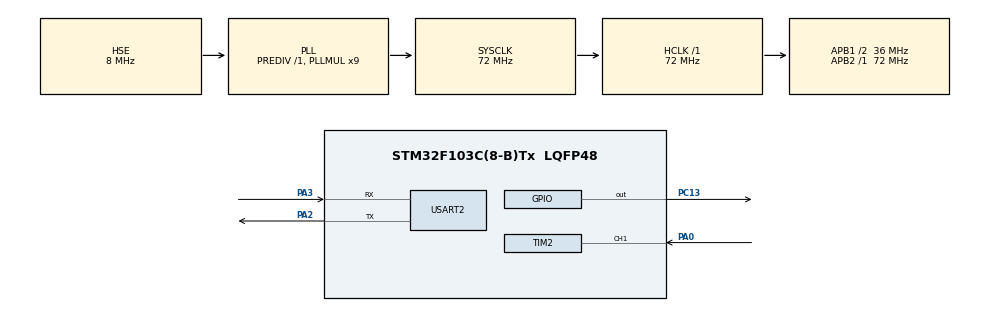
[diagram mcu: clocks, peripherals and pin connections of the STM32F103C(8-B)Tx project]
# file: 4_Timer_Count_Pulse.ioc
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Mcu.Family=STM32F1
RCC.PLLSourceVirtual=RCC_PLLSOURCE_HSE
PD1-OSC_OUT.Mode=HSE-External-Oscillator
PC13-TAMPER-RTC.Signal=GPIO_Output
PD0-OSC_IN.Signal=RCC_OSC_IN
RCC.APB1CLKDivider=RCC_HCLK_DIV2
RCC.SYSCLKSource=RCC_SYSCLKSOURCE_PLLCLK
ProjectManager.StackSize=0x400
PA0-WKUP.Signal=S_TIM2_CH1_ETR
PD1-OSC_OUT.Signal=RCC_OSC_OUT
PA13.Signal=SYS_JTMS-SWDIO
PA3.Mode=Asynchronous
ProjectManager.TargetToolchain=STM32CubeIDE
VP_TIM2_VS_ControllerModeClock.Mode=Clock Mode
RCC.HCLKFreq_Value=72000000
RCC.APB2TimFreq_Value=72000000
RCC.USBFreq_Value=72000000
RCC.AHBFreq_Value=72000000
PD0-OSC_IN.Mode=HSE-External-Oscillator
board=custom
RCC.PLLMUL=RCC_PLL_MUL9
RCC.APB2Freq_Value=72000000
PA14.Mode=Serial_Wire
TIM2.Period=1000
PA13.Mode=Serial_Wire
Mcu.Name=STM32F103C(8-B)Tx
PA2.Signal=USART2_TX
RCC.SYSCLKFreq_VALUE=72000000
Mcu.Package=LQFP48
USART2.VirtualMode=VM_ASYNC
SH.S_TIM2_CH1_ETR.0=TIM2_CH1,TriggerSource_TI1FP1
PA14.Signal=SYS_JTCK-SWCLK
ProjectManager.HeapSize=0x200
NVIC.PriorityGroup=NVIC_PRIORITYGROUP_4
RCC.APB1TimFreq_Value=72000000
PA2.Mode=Asynchronous
PA0-WKUP.GPIO_PuPd=GPIO_PULLDOWN
RCC.APB1Freq_Value=36000000
PA3.Signal=USART2_RX

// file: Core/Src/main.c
/* USER CODE BEGIN Header */
/**
  ******************************************************************************
  * @file           : main.c
  * @brief          : Main program body
  ******************************************************************************
  * @attention
  *
  * <h2><center>&copy; Copyright (c) 2021 STMicroelectronics.
  * All rights reserved.</center></h2>
  *
  * This software component is licensed by ST under BSD 3-Clause license,
  * the "License"; You may not use this file except in compliance with the
  * License. You may obtain a copy of the License at:
  *                        opensource.org/licenses/BSD-3-Clause
  *
  ******************************************************************************
  */
/* Input PA0 Pull down mode to prevent noise, which can cause problems
 * Using timer 2 to detect rising edge of pulse by pressing button*/

/* USER CODE END Header */
#include "main.h"

/* USER CODE BEGIN Includes */
#include "stdio.h"
/* USER CODE END Includes */

TIM_HandleTypeDef htim2;

UART_HandleTypeDef huart2;

void SystemClock_Config(void);
static void MX_GPIO_Init(void);
static void MX_TIM2_Init(void);
static void MX_USART2_UART_Init(void);

/* USER CODE BEGIN 0 */
uint8_t count ;
uint8_t temp ;
uint8_t Buff[4];
//This function for console view
int _write(int file, char *ptr, int len)
{
  /* Implement your write code here, this is used by puts and printf for example */
  int i=0;
  for(i=0 ; i<len ; i++)
    ITM_SendChar((*ptr++));
  return len;
}
/* USER CODE END 0 */

int main(void)
{

  /* MCU Configuration--------------------------------------------------------*/

  /* Reset of all peripherals, Initializes the Flash interface and the Systick. */
  HAL_Init();

  /* Configure the system clock */
  SystemClock_Config();

  /* Initialize all configured peripherals */
  MX_GPIO_Init();
  MX_TIM2_Init();
  MX_USART2_UART_Init();
  /* USER CODE BEGIN 2 */
	HAL_TIM_Base_Start(&htim2);
  /* USER CODE END 2 */

  /* Infinite loop */
  while (1)
  {

    /* USER CODE BEGIN 3 */
		count = (uint8_t)__HAL_TIM_GET_COUNTER(&htim2);
//		if(temp != count)
//		{
//			sprintf(Buff,"%d",count);
//			//HAL_UART_Transmit(&huart2, &temp, 1, HAL_MAX_DELAY);
//			HAL_GPIO_TogglePin(GPIOC, GPIO_PIN_13);
//			temp = count;
//			HAL_UART_Transmit(&huart2, Buff, 1, 500);
//		}

  }
  /* USER CODE END 3 */
}

void SystemClock_Config(void)
{
  RCC_OscInitTypeDef RCC_OscInitStruct = {0};
  RCC_ClkInitTypeDef RCC_ClkInitStruct = {0};

  /** Initializes the RCC Oscillators according to the specified parameters
  * in the RCC_OscInitTypeDef structure.
  */
  RCC_OscInitStruct.OscillatorType = RCC_OSCILLATORTYPE_HSE;
  RCC_OscInitStruct.HSEState = RCC_HSE_ON;
  RCC_OscInitStruct.HSEPredivValue = RCC_HSE_PREDIV_DIV1;
  RCC_OscInitStruct.HSIState = RCC_HSI_ON;
  RCC_OscInitStruct.PLL.PLLState = RCC_PLL_ON;
  RCC_OscInitStruct.PLL.PLLSource = RCC_PLLSOURCE_HSE;
  RCC_OscInitStruct.PLL.PLLMUL = RCC_PLL_MUL9;
  if (HAL_RCC_OscConfig(&RCC_OscInitStruct) != HAL_OK)
  {
    Error_Handler();
  }
  /** Initializes the CPU, AHB and APB buses clocks
  */
  RCC_ClkInitStruct.ClockType = RCC_CLOCKTYPE_HCLK|RCC_CLOCKTYPE_SYSCLK
                              |RCC_CLOCKTYPE_PCLK1|RCC_CLOCKTYPE_PCLK2;
  RCC_ClkInitStruct.SYSCLKSource = RCC_SYSCLKSOURCE_PLLCLK;
  RCC_ClkInitStruct.AHBCLKDivider = RCC_SYSCLK_DIV1;
  RCC_ClkInitStruct.APB1CLKDivider = RCC_HCLK_DIV2;
  RCC_ClkInitStruct.APB2CLKDivider = RCC_HCLK_DIV1;

  if (HAL_RCC_ClockConfig(&RCC_ClkInitStruct, FLASH_LATENCY_2) != HAL_OK)
  {
    Error_Handler();
  }
}

static void MX_TIM2_Init(void)
{

  TIM_SlaveConfigTypeDef sSlaveConfig = {0};
  TIM_MasterConfigTypeDef sMasterConfig = {0};

  htim2.Instance = TIM2;
  htim2.Init.Prescaler = 0;
  htim2.Init.CounterMode = TIM_COUNTERMODE_UP;
  htim2.Init.Period = 1000;
  htim2.Init.ClockDivision = TIM_CLOCKDIVISION_DIV1;
  htim2.Init.AutoReloadPreload = TIM_AUTORELOAD_PRELOAD_DISABLE;
  if (HAL_TIM_Base_Init(&htim2) != HAL_OK)
  {
    Error_Handler();
  }
  sSlaveConfig.SlaveMode = TIM_SLAVEMODE_EXTERNAL1;
  sSlaveConfig.InputTrigger = TIM_TS_TI1FP1;
  sSlaveConfig.TriggerPolarity = TIM_TRIGGERPOLARITY_RISING;
  sSlaveConfig.TriggerFilter = 0;
  if (HAL_TIM_SlaveConfigSynchro(&htim2, &sSlaveConfig) != HAL_OK)
  {
    Error_Handler();
  }
  sMasterConfig.MasterOutputTrigger = TIM_TRGO_RESET;
  sMasterConfig.MasterSlaveMode = TIM_MASTERSLAVEMODE_DISABLE;
  if (HAL_TIMEx_MasterConfigSynchronization(&htim2, &sMasterConfig) != HAL_OK)
  {
    Error_Handler();
  }

}

static void MX_USART2_UART_Init(void)
{

  huart2.Instance = USART2;
  huart2.Init.BaudRate = 115200;
  huart2.Init.WordLength = UART_WORDLENGTH_8B;
  huart2.Init.StopBits = UART_STOPBITS_1;
  huart2.Init.Parity = UART_PARITY_NONE;
  huart2.Init.Mode = UART_MODE_TX_RX;
  huart2.Init.HwFlowCtl = UART_HWCONTROL_NONE;
  huart2.Init.OverSampling = UART_OVERSAMPLING_16;
  if (HAL_UART_Init(&huart2) != HAL_OK)
  {
    Error_Handler();
  }

}

static void MX_GPIO_Init(void)
{
  GPIO_InitTypeDef GPIO_InitStruct = {0};

  /* GPIO Ports Clock Enable */
  __HAL_RCC_GPIOC_CLK_ENABLE();
  __HAL_RCC_GPIOD_CLK_ENABLE();
  __HAL_RCC_GPIOA_CLK_ENABLE();

  /*Configure GPIO pin Output Level */
  HAL_GPIO_WritePin(GPIOC, GPIO_PIN_13, GPIO_PIN_RESET);

  /*Configure GPIO pin : PC13 */
  GPIO_InitStruct.Pin = GPIO_PIN_13;
  GPIO_InitStruct.Mode = GPIO_MODE_OUTPUT_PP;
  GPIO_InitStruct.Pull = GPIO_NOPULL;
  GPIO_InitStruct.Speed = GPIO_SPEED_FREQ_LOW;
  HAL_GPIO_Init(GPIOC, &GPIO_InitStruct);

}

void Error_Handler(void)
{
  __disable_irq();
  while (1)
  {
  }
}

/************************ (C) COPYRIGHT STMicroelectronics *****END OF FILE****/
